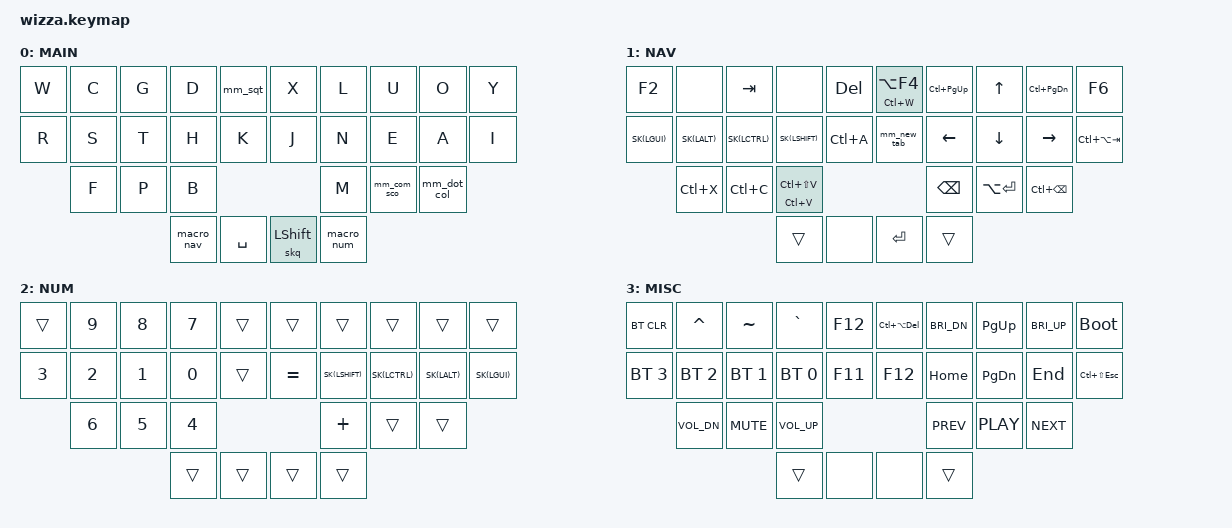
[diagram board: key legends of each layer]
/*
 * Copyright (c) 2020 The ZMK Contributors
 *
 * SPDX-License-Identifier: MIT
 */

#include <behaviors.dtsi>
#include <dt-bindings/zmk/keys.h>
#include <dt-bindings/zmk/bt.h>
#include <dt-bindings/zmk/outputs.h>

#define MAIN		0
#define NAV 		1
#define NUM			2
#define MISC		3

#define CAD			&kp LC(LA(DEL))
#define DEL_WORD	&kp LC(BSPC)
#define INCOGNITO	&kp LC(LS(N))
#define KILL		&ht LC(W) LA(F4)
#define NEW_LINE	&kp LA(ENTER)
#define SHO_APP_SEL &kp LC(LA(TAB))
#define SHO_COPY	&kp LC(C)
#define SHO_CUT		&kp LC(X)
#define SHO_PASTE	&ht LC(V) LC(LS(V))
#define SHO_SEL_ALL &kp LC(A)
#define SK(KEY) 	&nk KEY KEY
#define TAB_PREV	&kp LC(PG_UP)
#define TAB_NEW		&kp LC(T)
#define TAB_NEXT	&kp LC(PG_DN)
#define TASK_MAN	&kp LC(LS(ESC))

#define SLACK_1		&none
#define SLACK_2		&none

#define CON_ZERO	&bt BT_SEL 0
#define CON_ONE		&bt BT_SEL 1 
#define CON_TWO		&bt BT_SEL 2 
#define CON_THREE	&bt BT_SEL 3	

#define VOL_DOWN 	&kp C_VOL_DN 
#define VOL_UP		&kp C_VOL_UP 
#define VOL_MUTE	&kp C_MUTE

#define BRI_DN		&kp C_BRI_DN
#define BRI_UP		&kp C_BRI_UP

#include <dt-bindings/zmk/mouse.h>

#include "behaviors.dtsi"
#include "combos.dtsi"
#include "macros.dtsi"

#include <dt-bindings/zmk/mouse.h>

/ {	
	keymap {
		compatible = "zmk,keymap";
		
//						KEY POSITIONS
//		 0	 1	 2	 3	 4		 5	 6	 7	 8	 9
//		10	11	12	13	14		15	16	17	18	19 
//			20	21	22				23	24	25
//					26	27		28	29
//
//		 W	 C	 G	 D	 '		 X	 L	 U	 O	 Y
//		 R	 S	 T	 H	 K		 J	 N	 E	 A	 I 
//			 F	 P	 B				 M	 ,	 .
		
        main_layer {
            label = "MAIN";
            bindings = <
				&kp W		&kp C		&kp G		&kp D		&mm_sqt				&kp X		&kp L		&kp U		&kp O		&kp Y
				&kp R		&kp S		&kp T		&kp H		&kp K				&kp J		&kp N		&kp E		&kp A		&kp I
							&kp F		&kp P		&kp B                                       &kp M		&mm_com_sco	&mm_dot_col

													&macro_nav	&kp SPACE			&skq LSHIFT	&macro_num
			>;
		};

        nav_layer {
            label = "NAV"; // desk left and right can be swapped for other useful navigation for slack etc. insert?
			bindings = <
				&kp F2		SLACK_1		&kp TAB		SLACK_2		&kp DEL				KILL	 	TAB_PREV	&kp UP		TAB_NEXT	&kp F6
				SK(LGUI)	SK(LALT)	SK(LCTRL)	SK(LSHIFT)	SHO_SEL_ALL			&mm_new_tab	&kp LEFT	&kp DOWN	&kp RIGHT	SHO_APP_SEL
							SHO_CUT		SHO_COPY	SHO_PASTE                                   &kp BSPC	NEW_LINE	DEL_WORD

													&trans		&none				&kp RET		&trans
			>;
		};
	
        num_layer {
            label = "NUM";		
			bindings = <
				&trans		&kp N9		&kp N8		&kp N7		&trans				&trans		&trans		&trans		&trans		&trans
				&kp N3		&kp N2		&kp N1		&kp N0		&trans				&kp EQUAL	SK(LSHIFT)	SK(LCTRL)	SK(LALT)	SK(LGUI)
							&kp N6		&kp N5		&kp N4										&kp PLUS	&trans		&trans

													&trans		&trans				&trans		&trans
			>;
		};

		misc_layer {
            label = "MISC";		
            bindings = <
				&bt BT_CLR	&kp CARET	&kp TILDE	&kp GRAVE	&kp F12				CAD			BRI_DN		&kp PG_UP	BRI_UP		&bootloader
				CON_THREE	CON_TWO		CON_ONE		CON_ZERO	&kp F11				&kp F12		&kp HOME	&kp PG_DN	&kp END		TASK_MAN
							VOL_DOWN	VOL_MUTE	VOL_UP                                     	&kp C_PREV	&kp C_PLAY	&kp C_NEXT

													&trans		&none				&none		&trans
			>;
		};
	};
};

/*


ESSENTIAL SHORTCUTS
	- App Launch (replace START)
	- ESC
	- "
	- @
	- - 
	- _
	- !
	- ?
	- /
	- \
	- £ $ €
	- *
	- &

 ESC
 
 >-->--<!--<!--<!-->--<!-->--<!--<!--<!--<!--<!--<!--<!--<!-->--<!--<!-- l
https://github.com/rafaelromao/keyboards/tree/main
<!-- -->  macros <> (vertical) ll combo? ALT + ENTER FOR NEW LINE != COMBOS for ctrl K and ctrl F / html comments
	https://zmk.dev/docs/keymaps/behaviors/sticky-key#lazy
	CHANGE SPACE TO CANCEL ON MOD MORPH
	youtube, chrome, discord, slack, windows, explorer, joplin, drive/chrome/jira/confluence whatsapp =  shortcuts
	make sure markup is easy to get to 
	mute mic / what are shortcuts for teams, slack, huddle	https://slack.com/intl/en-gb/help/articles/202288908-Format-your-messages#:~:text=with%20special%20characters.-,Formatting%20toolbar,new%20line%2C%20press%20Shift%20Enter%20.>>
	close tab
	how to get to url bar
	vimium
	back / forward
	sticky shift
	// lock / ctrl alt del
	Leader key on right
	
	New passwords using home row https://word.tips/unscramble/rsthiaen/
	Add a Combo for BW
	
	Figure out best shortcuts for buttons VS good practice
	
	do I need a mouse button macro for STICK SHIFT SELECT cancel
	
	don't need capsword
	win swapper
	
	https://github.com/bmijanovich/zmk-config
	
	could also use ALT + Arrow keys for HOME/END etc'
	Numbers as functions
	Fix Del Word	
	Add SQT to macro_nav
	Shift and BSPC = DEL
	Hold SHO_PASE for paste special
	Add New Tab -> Hold for New Incognito
	Shortcut on NAV left hand for delete/backspace
	sort out custom shifts ,; .: ' ' a
	tidy up keymap drawer
	Slack shortcuts on right hand of misc https://www.thena.ai/post/slack-keyboard-shortcuts
	shift and enter for neww line
*/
